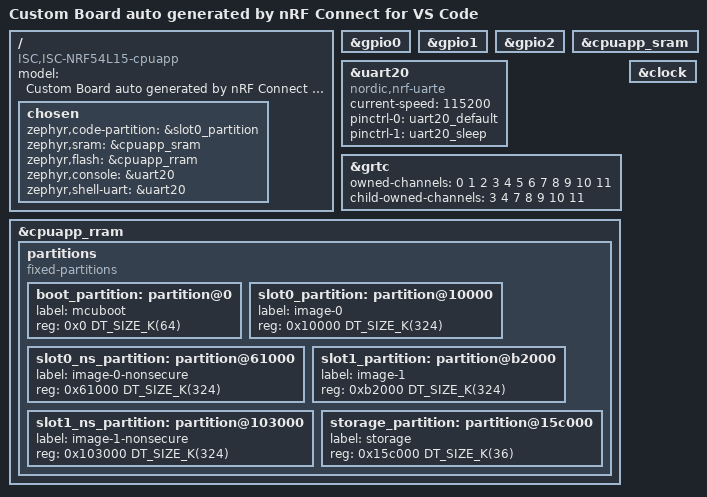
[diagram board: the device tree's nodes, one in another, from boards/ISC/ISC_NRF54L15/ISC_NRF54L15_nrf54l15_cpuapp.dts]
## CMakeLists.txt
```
cmake_minimum_required(VERSION 3.20.0)
find_package(Zephyr REQUIRED HINTS $ENV{ZEPHYR_BASE})

project(Test_Jig_demo)

set(COMMON_PATH ${CMAKE_CURRENT_LIST_DIR}/common)
include(${COMMON_PATH}/common.cmake)

target_sources(app PRIVATE src/main.c
                            app/com.c
                            app/test_commands.c
                            app/process.c
                            app/mac.c
                            # test_samples/adc/adc.c
                            # test_samples/pwm/pwm.c
                            # test_samples/spi/spi.c
                            # test_samples/i2c/i2c.c
                            # test_samples/usb/usb.c
                            # test_samples/nfc/nfc.c
                            # test_samples/nfc/ndef_file_m.c
                            test_samples/ble/ble.c
                            test_samples/gpio/gpio.c
                            # test_samples/sleep/sleep.c
                            )

target_include_directories(app PRIVATE app
                            # app PRIVATE test_samples/nfc
                            app PRIVATE common)
```

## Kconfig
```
#
# Copyright (c) 2018 Nordic Semiconductor
#
# SPDX-License-Identifier: LicenseRef-Nordic-5-Clause
#

source "Kconfig.zephyr"

menu "Nordic UART BLE GATT service sample"

config BT_NUS_THREAD_STACK_SIZE
	int "Thread stack size"
	default 1024
	help
	  Stack size used in each of the two threads

config BT_NUS_UART_BUFFER_SIZE
	int "UART payload buffer element size"
	default 40
	help
	  Size of the payload buffer in each RX and TX FIFO element

config BT_NUS_SECURITY_ENABLED
	bool "Enable security"
	default n
	select BT_SMP
	help
	  "Enable BLE security for the UART service"

config BT_NUS_UART_RX_WAIT_TIME
	int "Timeout for UART RX complete event"
	default 50000
	help
	  Wait for RX complete event time in microseconds

config SETTINGS
	default n

config ZMS
	default y if !(SOC_FLASH_NRF_RRAM || SOC_FLASH_NRF_MRAM)

config NVS
	default y if !(SOC_FLASH_NRF_RRAM || SOC_FLASH_NRF_MRAM)

endmenu
```

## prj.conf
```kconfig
CONFIG_UART_INTERRUPT_DRIVEN=y
CONFIG_NRFX_UARTE0=y
CONFIG_DK_LIBRARY=y
CONFIG_GPIO=y
# CONFIG_ADC=y
CONFIG_SERIAL=y
CONFIG_CONSOLE=y
CONFIG_UART_CONSOLE=y
CONFIG_PRINTK=y
CONFIG_CLOCK_CONTROL_NRF_K32SRC_RC=y
CONFIG_COUNTER=y
CONFIG_PM=y
CONFIG_PM_DEVICE=y

#Enable-USB
CONFIG_STDOUT_CONSOLE=y
CONFIG_USB_DEVICE_STACK=y
CONFIG_USB_DEVICE_PRODUCT="Zephyr CDC ACM sample"
CONFIG_USB_DEVICE_PID=0x0001
CONFIG_USB_DRIVER_LOG_LEVEL_ERR=y
CONFIG_USB_DEVICE_LOG_LEVEL_ERR=y
CONFIG_UART_LINE_CTRL=y
CONFIG_USB_DEVICE_INITIALIZE_AT_BOOT=n

#Enable-NFC
# CONFIG_NCS_SAMPLES_DEFAULTS=y
# CONFIG_NFC_T4T_NRFXLIB=n             
# CONFIG_NFC_NDEF=y
# CONFIG_NFC_NDEF_MSG=y
# CONFIG_NFC_NDEF_RECORD=y
# CONFIG_NFC_NDEF_URI_REC=y
# CONFIG_NFC_NDEF_URI_MSG=y

CONFIG_MPU_ALLOW_FLASH_WRITE=y
CONFIG_FLASH=y
CONFIG_FLASH_PAGE_LAYOUT=y
CONFIG_NVS=y

CONFIG_PWM=y
CONFIG_ASSERT=y
CONFIG_LOG=y
CONFIG_LOG_FRONTEND_ONLY=n
CONFIG_LOG_MODE_MINIMAL=n
CONFIG_LOG_PROCESS_THREAD=y
CONFIG_LOG_PROCESS_THREAD_SLEEP_MS=100

CONFIG_MAIN_STACK_SIZE=4096
CONFIG_SYSTEM_WORKQUEUE_STACK_SIZE=4096
CONFIG_HEAP_MEM_POOL_SIZE=4096

CONFIG_IDLE_STACK_SIZE=4096

CONFIG_BOOT_BANNER=n
CONFIG_NCS_BOOT_BANNER=n

#Enable-bluetooth
CONFIG_BT=y
CONFIG_BT_DEVICE_NAME="ISC_TEST_DEMO"
CONFIG_BT_PERIPHERAL=y
CONFIG_BT_CTLR_TX_PWR_PLUS_8=y
CONFIG_BT_HCI=y

#Enable nrfx-spi
# CONFIG_NRFX_SPIM3=y
# CONFIG_NRFX_SPIS2=y
# CONFIG_SPI=n

# # Enable nrfx-twi
# CONFIG_NRFX_TWIM0=y
# CONFIG_NRFX_TWIS1=y
# CONFIG_I2C=n

# CONFIG_NFCT_PINS_AS_GPIOS=y


CONFIG_CLOCK_CONTROL_NRF_K32SRC_XTAL=n
CONFIG_CLOCK_CONTROL_NRF_K32SRC_500PPM=y
CONFIG_CLOCK_CONTROL_NRF_K32SRC_RC_CALIBRATION=y

CONFIG_MPSL=y
CONFIG_BT_LL_SOFTDEVICE=y  

CONFIG_CLOCK_CONTROL=y
CONFIG_CLOCK_CONTROL_NRF=y
CONFIG_RING_BUFFER=y

CONFIG_GPIO=y


CONFIG_SPI_NOR=n
CONFIG_NORDIC_QSPI_NOR=n
CONFIG_NRFX_SPIM00=n
CONFIG_NRFX_UARTE00=n

# CONFIG_UART_ASYNC_API=y
CONFIG_HWINFO=y 

CONFIG_NRF_APPROTECT_DISABLE=y
```

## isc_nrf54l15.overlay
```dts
// &lfxo {
//     status = "okay";
// };

// &hfxo {
//     status = "okay";
//     load-capacitors = "internal";
//     load-capacitance-femtofarad = <15500>;
// };

&uicr {
    nfct-pins-as-gpios;
    gpio-as-nreset;
};


&gpiote20 {
    status = "okay";
};

&gpiote30 {
    status = "okay";
};

&spi00 {
    status = "disabled";
};

&nfct {
    status = "disabled";
};

// &qspi{
//     status = "disabled";
// };

&spi20 {
    status = "disabled";
};

&uart00 {
    status = "disabled";
};

&pinctrl {
    /omit-if-no-ref/ spi00_default: spi00_default {};
    /omit-if-no-ref/ spi00_sleep: spi00_sleep {};
};
```

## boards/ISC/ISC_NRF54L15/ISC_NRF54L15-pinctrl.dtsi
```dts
&pinctrl {
     uart20_default: uart20_default {
        group1 {
            psels = <NRF_PSEL(UART_TX, 1, 4)>;
        };
        group2 {
            psels = <NRF_PSEL(UART_RX, 1, 5)>;
            bias-pull-up;
        };
    };

    uart20_sleep: uart20_sleep {
        group1 {
            psels = <NRF_PSEL(UART_TX, 1, 4)>,
                    <NRF_PSEL(UART_RX, 1, 5)>;
            low-power-enable;
        };
    };
};
```

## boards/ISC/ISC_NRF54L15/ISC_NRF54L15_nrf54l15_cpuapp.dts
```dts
/dts-v1/;
#include <nordic/nrf54l15_cpuapp.dtsi>
#include "ISC_NRF54L15-pinctrl.dtsi"

/ {
	model = "Custom Board auto generated by nRF Connect for VS Code";
	compatible = "ISC,ISC-NRF54L15-cpuapp";

	chosen {
		zephyr,code-partition = &slot0_partition;
		zephyr,sram = &cpuapp_sram;
		zephyr,flash = &cpuapp_rram;
		zephyr,console = &uart20;       // added
        zephyr,shell-uart = &uart20;    // added
	};
};

&gpio0 {
    status = "okay";
};

&gpio1 {
    status = "okay";
};

&gpio2 {
    status = "okay";
};


&uart20 {
    compatible = "nordic,nrf-uarte";
    status = "okay";
    current-speed = <115200>;
    pinctrl-0 = <&uart20_default>;
    pinctrl-1 = <&uart20_sleep>;
    pinctrl-names = "default", "sleep";
};

&cpuapp_sram {
	status = "okay";
};

&grtc {
	owned-channels = <0 1 2 3 4 5 6 7 8 9 10 11>;
	/* Channels 7-11 reserved for Zero Latency IRQs, 3-4 for FLPR */
	child-owned-channels = <3 4 7 8 9 10 11>;
	status = "okay";
};

&cpuapp_rram {
	partitions {
		compatible = "fixed-partitions";
		#address-cells = <1>;
		#size-cells = <1>;
		boot_partition: partition@0 {
			label = "mcuboot";
			reg = <0x0 DT_SIZE_K(64)>;
		};
		slot0_partition: partition@10000 {
			label = "image-0";
			reg = <0x10000 DT_SIZE_K(324)>;
		};
		slot0_ns_partition: partition@61000 {
			label = "image-0-nonsecure";
			reg = <0x61000 DT_SIZE_K(324)>;
		};
		slot1_partition: partition@b2000 {
			label = "image-1";
			reg = <0xb2000 DT_SIZE_K(324)>;
		};
		slot1_ns_partition: partition@103000 {
			label = "image-1-nonsecure";
			reg = <0x103000 DT_SIZE_K(324)>;
		};
		/* 32k from 0x154000 to 0x15bfff reserved for TF-M partitions */
		storage_partition: partition@15c000 {
			label = "storage";
			reg = <0x15c000 DT_SIZE_K(36)>;
		};
	};
};

// &lfxo {
//     status = "okay";
//     load-capacitors = "internal";
//     load-capacitance-femtofarad = <15500>;
// };

&clock {
    status = "okay";
};


// &hfxo {
//     status = "okay";
//     load-capacitors = "internal";
//     load-capacitance-femtofarad = <15500>;
// };
```

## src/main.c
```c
#include <zephyr/kernel.h>
#include <zephyr/device.h>
#include <zephyr/devicetree.h>
#include <zephyr/drivers/uart.h>
#include <zephyr/drivers/gpio.h>
#include <zephyr/sys/printk.h>

#include <com.h>
#include <test_commands.h>
#include <process.h>


int main(void)
{
        begin();
        return 0;
}
```
